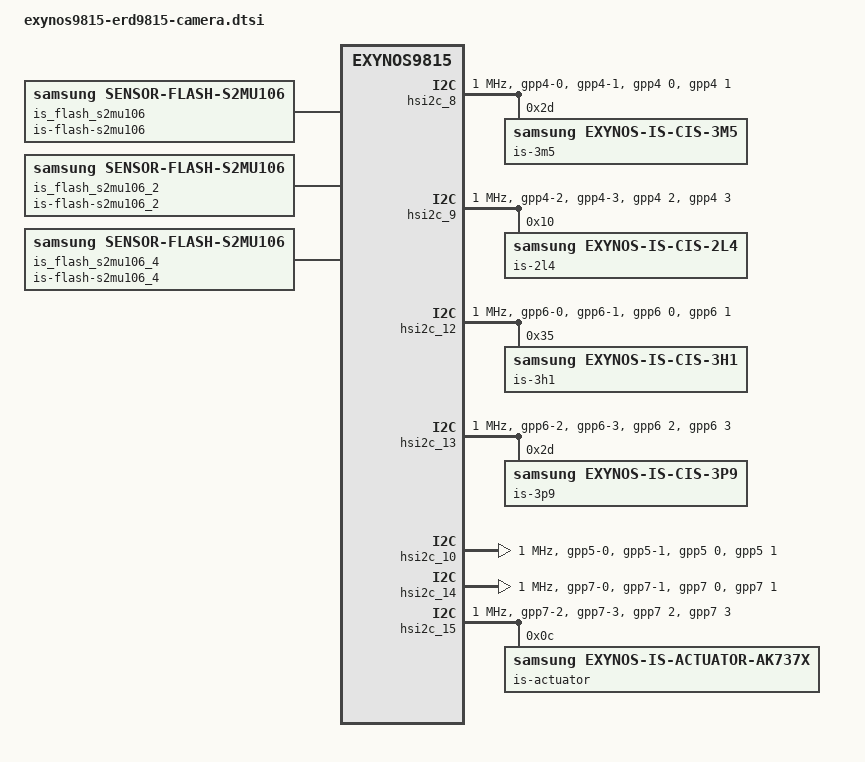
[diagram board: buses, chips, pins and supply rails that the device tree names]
/*
 * Samsung Exynos SoC series Pablo driver
 *
 * Copyright (c) 2020 Samsung Electronics Co., Ltd
 *
 * This program is free software; you can redistribute it and/or modify
 * it under the terms of the GNU General Public License version 2 as
 * published by the Free Software Foundation.
 */

#include <dt-bindings/camera/exynos_is_dt.h>

#include "camera/module_2l4.dtsi"
#include "camera/module_3m5.dtsi"
#include "camera/module_3p9.dtsi"
#include "camera/module_3h1.dtsi"

/ {
	fragment@camera {
		target-path = "/";
		__overlay__ {
			#address-cells = <2>;
			#size-cells = <1>;
			interrupt-parent = <&gic>;

			/* REAR CAMERA */
			is_sensor_2l4: is_sensor_2l4@20 {
				pinctrl-names = "pin0", "pin1", "pin2", "release";
				pinctrl-0 = <>;
				pinctrl-1 = <&sensor_mclk0_out>;
				pinctrl-2 = <&sensor_mclk0_fn>;
				pinctrl-3 = <>;

				/* board */
				position = <0>;	/* Rear:0. Front:1. Rear_sub:2. Secure:3. */
				id = <0>; /* is_sensor id */
				mclk_ch = <0>;
				sensor_i2c_ch = <1>; /* SENSOR_CONTROL_I2C1 */

				/* peri */
				af {
					product_name = <18>; /* ACTUATOR_NAME_AK737X : ak7371 or ak7374 */
					i2c_ch = <3>; /* SENSOR_CONTROL_I2C3 */
				};

				flash {
					product_name = <14>; /* S2MU106 */
				};

				ois {
					product_name = <100>; /* NOTHING */
				};

				vc_extra {
					/* ex) statX = <stat_type, sensor_mode, max_width, max_height, max_element> */
					stat0 = </* not avaliable */>;									/* VC_BUF_DATA_TYPE_SENSOR_STAT1 */
					stat1 = </*VC_STAT_TYPE_PDP_3_1_PDAF_STAT0*/ 1000 /*VC_SENSOR_MODE_2PD_MODE3*/ 102 1756 1 1>;	/* VC_BUF_DATA_TYPE_GENERAL_STAT1 */
					stat2 = </* not avaliable */>;									/* VC_BUF_DATA_TYPE_SENSOR_STAT2 */
					stat3 = </*VC_STAT_TYPE_PDP_3_1_PDAF_STAT1*/ 1001 /*VC_SENSOR_MODE_2PD_MODE3*/ 102 39424 1 1>;	/* VC_BUF_DATA_TYPE_GENERAL_STAT2 */
				};

				modes {
					mode0 {
						common = <4032 3024 30 0 0 CSI_DATA_LANES_4 2054 CSI_MODE_VC_DT LRTE_DISABLE PD_MOD3 EX_NONE>;
						vc3 = </* in */ 0 HW_FORMAT_EMBEDDED_8BIT 0 0	/* out */ HW_FORMAT_USER VC_PRIVATE 1756 1>;
					};
					mode1 {
						common = <4032 2268 60 0 1 CSI_DATA_LANES_4 2177 CSI_MODE_VC_DT LRTE_DISABLE PD_MOD3 EX_NONE>;
						vc3 = </* in */ 0 HW_FORMAT_EMBEDDED_8BIT 0 0	/* out */ HW_FORMAT_USER VC_PRIVATE 1756 1>;
					};
					mode2 {
						common = <4032 2268 30 0 2 CSI_DATA_LANES_4 2054 CSI_MODE_VC_DT LRTE_DISABLE PD_MOD3 EX_NONE>;
						vc3 = </* in */ 0 HW_FORMAT_EMBEDDED_8BIT 0 0	/* out */ HW_FORMAT_USER VC_PRIVATE 1756 1>;
					};
					mode3 {
						common = <4032 1908 30 0 3 CSI_DATA_LANES_4 2054 CSI_MODE_VC_DT LRTE_DISABLE PD_MOD3 EX_NONE>;
						vc3 = </* in */ 0 HW_FORMAT_EMBEDDED_8BIT 0 0	/* out */ HW_FORMAT_USER VC_PRIVATE 1756 1>;
					};
					mode4 {
						common = <3024 3024 30 0 4 CSI_DATA_LANES_4 2054 CSI_MODE_VC_DT LRTE_DISABLE PD_MOD3 EX_NONE>;
						vc3 = </* in */ 0 HW_FORMAT_EMBEDDED_8BIT 0 0	/* out */ HW_FORMAT_USER VC_PRIVATE 1756 1>;
					};
					mode5 {
						common = <2016 1512 30 0 5 CSI_DATA_LANES_4 1352 CSI_MODE_VC_DT LRTE_DISABLE PD_MOD3 EX_NONE>;
						vc3 = </* in */ 0 HW_FORMAT_EMBEDDED_8BIT 0 0	/* out */ HW_FORMAT_USER VC_PRIVATE 1756 1>;
					};
					mode6 {
						common = <2016 1134 30 0 6 CSI_DATA_LANES_4 1352 CSI_MODE_VC_DT LRTE_DISABLE PD_MOD3 EX_NONE>;
						vc3 = </* in */ 0 HW_FORMAT_EMBEDDED_8BIT 0 0	/* out */ HW_FORMAT_USER VC_PRIVATE 1756 1>;
					};
					mode7 {
						common = <1504 1504 30 0 7 CSI_DATA_LANES_4 1352 CSI_MODE_VC_DT LRTE_DISABLE PD_MOD3 EX_NONE>;
						vc3 = </* in */ 0 HW_FORMAT_EMBEDDED_8BIT 0 0	/* out */ HW_FORMAT_USER VC_PRIVATE 1756 1>;
					};
					/* MODE 3 - 24fps LIVE FOCUS */
					mode8 {
						common = <4032 3024 24 0 8 CSI_DATA_LANES_4 2054 CSI_MODE_VC_DT LRTE_DISABLE PD_MOD3 EX_LIVEFOCUS>;
						vc3 = </* in */ 0 HW_FORMAT_EMBEDDED_8BIT 0 0	/* out */ HW_FORMAT_USER VC_PRIVATE 1756 1>;
					};
					mode9 {
						common = <4032 2268 24 0 9 CSI_DATA_LANES_4 2054 CSI_MODE_VC_DT LRTE_DISABLE PD_MOD3 EX_LIVEFOCUS>;
						vc3 = </* in */ 0 HW_FORMAT_EMBEDDED_8BIT 0 0	/* out */ HW_FORMAT_USER VC_PRIVATE 1756 1>;
					};
					mode10 {
						common = <4032 1908 24 0 10 CSI_DATA_LANES_4 2054 CSI_MODE_VC_DT LRTE_DISABLE PD_MOD3 EX_LIVEFOCUS>;
						vc3 = </* in */ 0 HW_FORMAT_EMBEDDED_8BIT 0 0	/* out */ HW_FORMAT_USER VC_PRIVATE 1756 1>;
					};
					mode11 {
						common = <3024 3024 24 0 11 CSI_DATA_LANES_4 2054 CSI_MODE_VC_DT LRTE_DISABLE PD_MOD3 EX_LIVEFOCUS>;
						vc3 = </* in */ 0 HW_FORMAT_EMBEDDED_8BIT 0 0	/* out */ HW_FORMAT_USER VC_PRIVATE 1756 1>;
					};
					/* MODE 2 */
					mode12 {
						common = <2016 1134 240 0 12 CSI_DATA_LANES_4 2054 CSI_MODE_VC_DT LRTE_DISABLE PD_NONE EX_NONE>;
						vc3 = </* in */ 0 HW_FORMAT_EMBEDDED_8BIT 0 0	/* out */ HW_FORMAT_UNKNOWN VC_NOTHING 0 0>;
					};
					mode13 {
						common = <1008 756 120 0 13 CSI_DATA_LANES_4 2054 CSI_MODE_VC_DT LRTE_DISABLE PD_NONE EX_NONE>;
						vc3 = </* in */ 0 HW_FORMAT_EMBEDDED_8BIT 0 0	/* out */ HW_FORMAT_UNKNOWN VC_NOTHING 0 0>;
					};
				};

				power_seq {
					use = <1>;
					gpio_mclk = <&gpg1 0 0x1>;

					scenario_normal_on {
						sensor_scenario = <SENSOR_SCENARIO_NORMAL>;
						gpio_scenario = <GPIO_SCENARIO_ON>;

						/* A start node number should be over the 10 for reserved number 0~9. */
						/* pname = "name"; pin = <act value dealy voltage>; gpio = <gpx# # 0x1>; */
						10 { pname = "sen_rst low"; pin = <PIN_OUTPUT 0 0>; gpio = <&gpg3 1 0x1>; };
						20 { pname = "VDDD_RET_1.0V_CAM"; pin = <PIN_REGULATOR 1 1 1025000>; };
						30 { pname = "VDDA_2.8V_SUB"; pin = <PIN_REGULATOR 1 0>; };
						40 { pname = "VDDA_2.8V_CAM"; pin = <PIN_REGULATOR 1 1>; };
						50 { pname = "VDDD_1.05V_SUB"; pin = <PIN_REGULATOR 1 1>; };
						60 { pname = "VDD_VM_2.8V_OIS"; pin = <PIN_REGULATOR 1 1>; };
						70 { pname = "VDDIO_1.8V_CAM"; pin = <PIN_REGULATOR 1 1>; };
						80 { pname = "VDDD_1.05V_CAM"; pin = <PIN_REGULATOR 1 1000>; };
						90 { pname; pin; };
						100 { pname; pin; };
						110 { pname = "on_i2c"; pin = <PIN_I2C 1 0>; };
						120 { pname = "pin"; pin = <PIN_FUNCTION 2 0>; };
						130 { pname = "MCLK"; pin = <PIN_MCLK 1 1500>; share = <SRT_ACQUIRE SHARED_PIN0 1>; };
						140 { pname = "sen_rst high"; pin = <PIN_OUTPUT 1 3000>; gpio = <&gpg3 1 0x1>; };
						150 { pname; pin; gpio; };
					};

					scenario_vision_on {
						sensor_scenario = <SENSOR_SCENARIO_VISION>;
						gpio_scenario = <GPIO_SCENARIO_ON>;

						/* A start node number should be over the 10 for reserved number 0~9. */
						/* pname = "name"; pin = <act value dealy voltage>; gpio = <gpx# # 0x1>; */
						10 { pname = "sen_rst low"; pin = <PIN_OUTPUT 0 0>; gpio = <&gpg3 1 0x1>; };
						20 { pname = "VDDD_RET_1.0V_CAM"; pin = <PIN_REGULATOR 1 1 1025000>; };
						30 { pname = "VDDA_2.8V_SUB"; pin = <PIN_REGULATOR 1 0>; };
						40 { pname = "VDDA_2.8V_CAM"; pin = <PIN_REGULATOR 1 1>; };
						50 { pname = "VDDD_1.05V_SUB"; pin = <PIN_REGULATOR 1 1>; };
						60 { pname = "VDD_VM_2.8V_OIS"; pin = <PIN_REGULATOR 1 1>; };
						70 { pname = "VDDIO_1.8V_CAM"; pin = <PIN_REGULATOR 1 1>; };
						80 { pname = "VDDD_1.05V_CAM"; pin = <PIN_REGULATOR 1 1000>; };
						90 { pname; pin; };
						100 { pname; pin; };
						110 { pname = "on_i2c"; pin = <PIN_I2C 1 0>; };
						120 { pname = "pin"; pin = <PIN_FUNCTION 2 0>; };
						130 { pname = "MCLK"; pin = <PIN_MCLK 1 1500>; share = <SRT_ACQUIRE SHARED_PIN0 1>; };
						140 { pname = "sen_rst high"; pin = <PIN_OUTPUT 1 3000>; gpio = <&gpg3 1 0x1>; };
						150 { pname; pin; gpio; };
					};

					scenario_hw_init_normal_on {
						/* HW INIT (without ois power control) */
						sensor_scenario = <SENSOR_SCENARIO_HW_INIT>;
						gpio_scenario = <GPIO_SCENARIO_ON>;

						10 { pname; pin; gpio; };
						20 { pname; pin; gpio; };
						30 { pname; pin; gpio; };
						40 { pname; pin; gpio; };
						50 { pname; pin; gpio; };
						60 { pname; pin; gpio; };
						70 { pname; pin; gpio; };
						80 { pname; pin; gpio; };
						90 { pname; pin; gpio; };
						100 { pname; pin; gpio; };
						110 { pname; pin; gpio; };
						120 { pname; pin; gpio; };
					};

					scenario_normal_off {
						sensor_scenario = <SENSOR_SCENARIO_NORMAL>;
						gpio_scenario = <GPIO_SCENARIO_OFF>;

						/* A start node number should be over the 10 for reserved number 0~9. */
						/* pname = "name"; pin = <act value dealy voltage>; gpio = <gpx# # 0x1>; */
						10 { pname = "VDD_VM_2.8V_OIS"; pin = <PIN_REGULATOR 0 10>; };
						20 { pname = "VDDD_1.05V_CAM"; pin = <PIN_REGULATOR 0 1>; };
						30 { pname = "VDDD_1.05V_SUB"; pin = <PIN_REGULATOR 0 10>; };
						40 { pname = "VDDA_2.8V_SUB"; pin = <PIN_REGULATOR 0 0>; };
						50 { pname = "VDDA_2.8V_CAM"; pin = <PIN_REGULATOR 0 0>; };
						60 { pname = "MCLK"; pin = <PIN_MCLK 0 0>; share = <SRT_RELEASE SHARED_PIN0 0>; };
						70 { pname = "pin"; pin = <PIN_FUNCTION 0 0>; };
						80 { pname = "pin"; pin = <PIN_FUNCTION 1 0>; };
						90 { pname = "pin"; pin = <PIN_FUNCTION 0 0>; };
						100 { pname = "sen_rst low"; pin = <PIN_OUTPUT 0 10>; gpio = <&gpg3 1 0x1>; };
						110 { pname; pin; gpio; };
						120 { pname = "off_i2c"; pin = <PIN_I2C 0 0>; };
						130 { pname; pin; gpio; };
						140 { pname; pin; gpio; };
						150 { pname = "VDDD_RET_1.0V_CAM"; pin = <PIN_REGULATOR 0 100>; };
						160 { pname = "VDDIO_1.8V_CAM"; pin = <PIN_REGULATOR 0 10>; };
					};

					scenario_vision_off {
						sensor_scenario = <SENSOR_SCENARIO_VISION>;
						gpio_scenario = <GPIO_SCENARIO_OFF>;

						/* A start node number should be over the 10 for reserved number 0~9. */
						/* pname = "name"; pin = <act value dealy voltage>; gpio = <gpx# # 0x1>; */
						10 { pname = "VDD_VM_2.8V_OIS"; pin = <PIN_REGULATOR 0 10>; };
						20 { pname = "VDDD_1.05V_CAM"; pin = <PIN_REGULATOR 0 1>; };
						30 { pname = "VDDD_1.05V_SUB"; pin = <PIN_REGULATOR 0 10>; };
						40 { pname = "VDDA_2.8V_SUB"; pin = <PIN_REGULATOR 0 0>; };
						50 { pname = "VDDA_2.8V_CAM"; pin = <PIN_REGULATOR 0 0>; };
						60 { pname = "MCLK"; pin = <PIN_MCLK 0 0>; share = <SRT_RELEASE SHARED_PIN0 0>; };
						70 { pname = "pin"; pin = <PIN_FUNCTION 0 0>; };
						80 { pname = "pin"; pin = <PIN_FUNCTION 1 0>; };
						90 { pname = "pin"; pin = <PIN_FUNCTION 0 0>; };
						100 { pname = "sen_rst low"; pin = <PIN_OUTPUT 0 10>; gpio = <&gpg3 1 0x1>; };
						110 { pname; pin; gpio; };
						120 { pname = "off_i2c"; pin = <PIN_I2C 0 0>; };
						130 { pname; pin; gpio; };
						140 { pname; pin; gpio; };
						150 { pname = "VDDD_RET_1.0V_CAM"; pin = <PIN_REGULATOR 0 100>; };
						160 { pname = "VDDIO_1.8V_CAM"; pin = <PIN_REGULATOR 0 10>; };
					};

					scenario_retention_on {
						sensor_scenario = <SENSOR_SCENARIO_NORMAL>;
						gpio_scenario = <GPIO_SCENARIO_SENSOR_RETENTION_ON>;

						/* A start node number should be over the 10 for reserved number 0~9. */
						/* pname = "name"; pin = <act value dealy voltage>; gpio = <gpx# # 0x1>; */
						10 { pname; pin; gpio; };
						20 { pname; pin; gpio; };
						30 { pname; pin; gpio; };
						40 { pname; pin; gpio; };
						50 { pname; pin; gpio; };
						60 { pname; pin; gpio; };
						70 { pname; pin; gpio; };
						80 { pname; pin; gpio; };
						90 { pname; pin; gpio; };
						100 { pname; pin; gpio; };
						110 { pname; pin; gpio; };
						120 { pname; pin; gpio; };
						130 { pname; pin; gpio; };
						140 { pname; pin; gpio; };
						150 { pname; pin; gpio; };
					};

					scenario_hw_init_retention_on {
						/* RETENTION ON HW INIT(without ois power control) */
						sensor_scenario = <SENSOR_SCENARIO_HW_INIT>;
						gpio_scenario = <GPIO_SCENARIO_SENSOR_RETENTION_ON>;

						10 { pname; pin; gpio; };
						20 { pname; pin; gpio; };
						30 { pname; pin; gpio; };
						40 { pname; pin; gpio; };
						50 { pname; pin; gpio; };
						60 { pname; pin; gpio; };
						70 { pname; pin; gpio; };
						80 { pname; pin; gpio; };
						90 { pname; pin; gpio; };
						100 { pname; pin; gpio; };
						110 { pname; pin; gpio; };
						120 { pname; pin; gpio; };
					};

					scenario_ois_factory_on {
						sensor_scenario = <SENSOR_SCENARIO_OIS_FACTORY>;
						gpio_scenario = <GPIO_SCENARIO_ON>;

						/* A start node number should be over the 10 for reserved number 0~9. */
						/* pname = "name"; pin = <act value dealy voltage>; gpio = <gpx# # 0x1>; */
						10 { pname; pin; gpio; };
						20 { pname; pin; gpio; };
						30 { pname; pin; gpio; };
						40 { pname; pin; gpio; };
						50 { pname; pin; gpio; };
						60 { pname; pin; gpio; };
						70 { pname; pin; gpio; };
					};

					scenario_ois_factory_off {
						sensor_scenario = <SENSOR_SCENARIO_OIS_FACTORY>;
						gpio_scenario = <GPIO_SCENARIO_OFF>;

						/* A start node number should be over the 10 for reserved number 0~9. */
						/* pname = "name"; pin = <act value dealy voltage>; gpio = <gpx# # 0x1>; */
						10 { pname; pin; gpio; };
						20 { pname; pin; gpio; };
						30 { pname; pin; gpio; };
						40 { pname; pin; gpio; };
						50 { pname; pin; gpio; };
						60 { pname; pin; gpio; };
						70 { pname; pin; gpio; };
					};

					scenario_read_rom_on {
						sensor_scenario = <SENSOR_SCENARIO_READ_ROM>;
						gpio_scenario = <GPIO_SCENARIO_ON>;

						/* A start node number should be over the 10 for reserved number 0~9. */
						/* pname = "name"; pin = <act value dealy voltage>; gpio = <gpx# # 0x1>; */
						10 { pname; pin; gpio; };
						20 { pname; pin; gpio; };
						30 { pname; pin; gpio; };
						40 { pname; pin; gpio; };
					};

					scenario_read_rom_off {
						sensor_scenario = <SENSOR_SCENARIO_READ_ROM>;
						gpio_scenario = <GPIO_SCENARIO_OFF>;

						/* A start node number should be over the 10 for reserved number 0~9. */
						/* pname = "name"; pin = <act value dealy voltage>; gpio = <gpx# # 0x1>; */
						10 { pname; pin; gpio; };
						20 { pname; pin; gpio; };
						30 { pname; pin; gpio; };
						40 { pname; pin; gpio; };
					};
				};
			};

			/* Tele CAMERA */
			is_sensor_3m5: is_sensor_3m5@64 {
				pinctrl-names = "pin0", "pin1", "pin2", "release";
				pinctrl-0 = <>;
				pinctrl-1 = <&sensor_mclk0_out>;
				pinctrl-2 = <&sensor_mclk0_fn>;
				pinctrl-3 = <>;

				/* board */
				position = <2>; /* Rear:0. Front:1, Tele:2 */
				id = <2>; /* is_sensor id */
				mclk_ch = <0>;
				sensor_i2c_ch = <0>; /* SENSOR_CONTROL_I2C0 */

				af {
					product_name = <100>; /* NOTHING */
				};

				flash {
					product_name = <14>; /* S2MU106 */
				};

				preprocessor {
					product_name = <100>; /* NOTHING */
				};

				vc_extra {
					/* ex) statX = <stat_type, sensor_mode, max_width, max_height, max_element> */
					stat0 = </* not avaliable */>;			/* VC_BUF_DATA_TYPE_SENSOR_STAT1 */
					stat1 = </* not avaliable */>;			/* VC_BUF_DATA_TYPE_SENSOR_STAT1 */
					stat2 = </* not avaliable */>;			/* VC_BUF_DATA_TYPE_SENSOR_STAT2 */
					stat3 = </* not avaliable */>;			/* VC_BUF_DATA_TYPE_SENSOR_STAT2 */
				};

				/* sensor modes */
				modes {
					/* common = <width, height, fps, settle, mode, lane, speed, interleave, lrte, pd_mode> */
					/* vcX = <map, hwformat, width, height, hwformat, type, width, height> */
					mode0 {
						common = <4032 3024 30 0 0 CSI_DATA_LANES_4 1352 CSI_MODE_VC_ONLY LRTE_DISABLE PD_NONE EX_NONE>;
						vc1 = </* in */ 1 HW_FORMAT_RAW10 504 752	/* out */ HW_FORMAT_UNKNOWN VC_NOTHING 0 0>;
					};
					mode1 {
						common = <4032 2268 30 0 1 CSI_DATA_LANES_4 1352 CSI_MODE_VC_ONLY LRTE_DISABLE PD_NONE EX_NONE>;
						vc1 = </* in */ 1 HW_FORMAT_RAW10 504 560	/* out */ HW_FORMAT_UNKNOWN VC_NOTHING 0 0>;
					};
					mode2 {
						common = <3024 3024 30 0 2 CSI_DATA_LANES_4 1352 CSI_MODE_VC_ONLY LRTE_DISABLE PD_NONE EX_NONE>;
						vc1 = </* in */ 1 HW_FORMAT_RAW10 376 752	/* out */ HW_FORMAT_UNKNOWN VC_NOTHING 0 0>;
					};
					mode3 {
						common = <4032 1960 30 0 3 CSI_DATA_LANES_4 1352 CSI_MODE_VC_ONLY LRTE_DISABLE PD_NONE EX_NONE>;
						vc1 = </* in */ 1 HW_FORMAT_RAW10 504 480	/* out */ HW_FORMAT_UNKNOWN VC_NOTHING 0 0>;
					};
					mode4 {
						common = <4032 1908 30 0 4 CSI_DATA_LANES_4 1352 CSI_MODE_VC_ONLY LRTE_DISABLE PD_NONE EX_NONE>;
						vc1 = </* in */ 1 HW_FORMAT_RAW10 504 464	/* out */ HW_FORMAT_UNKNOWN VC_NOTHING 0 0>;
					};
					mode5 {
						common = <1920 1080 60 0 5 CSI_DATA_LANES_4 1352 CSI_MODE_VC_ONLY LRTE_DISABLE PD_NONE EX_NONE>;
						vc1 = </* in */ 1 HW_FORMAT_RAW10 240 256	/* out */ HW_FORMAT_UNKNOWN VC_NOTHING 0 0>;
					};
					mode7 {
						common = <2016 1512 30 0 7 CSI_DATA_LANES_4 1352 CSI_MODE_VC_ONLY LRTE_DISABLE PD_NONE EX_NONE>;
						vc1 = </* in */ 1 HW_FORMAT_RAW10 504 752	/* out */ HW_FORMAT_UNKNOWN VC_NOTHING 0 0>;
					};
					mode8 {
						common = <1504 1504 30 0 8 CSI_DATA_LANES_4 1352 CSI_MODE_VC_ONLY LRTE_DISABLE PD_NONE EX_NONE>;
						vc1 = </* in */ 1 HW_FORMAT_RAW10 376 752	/* out */ HW_FORMAT_UNKNOWN VC_NOTHING 0 0>;
					};
					mode9 {
						common = <2016 1134 30 0 9 CSI_DATA_LANES_4 1352 CSI_MODE_VC_ONLY LRTE_DISABLE PD_NONE EX_NONE>;
						vc1 = </* in */ 1 HW_FORMAT_RAW10 504 560	/* out */ HW_FORMAT_UNKNOWN VC_NOTHING 0 0>;
					};
				};

				power_seq {
					use = <1>;
					gpio_mclk = <&gpg1 0 0x1>;

					scenario_normal_on {
						sensor_scenario = <SENSOR_SCENARIO_NORMAL>;
						gpio_scenario = <GPIO_SCENARIO_ON>;

						/* A start node number should be over the 10 for reserved number 0~9. */
						/* pname = "name"; pin = <act value dealy voltage>; gpio = <gpx# # 0x1>; */
						10 { pname = "sen_rst low"; pin = <PIN_OUTPUT 0 0>; gpio = <&gpg3 2 0x1>; };
						20 { pname = "S2MPB02_LDO11"; pin = <PIN_REGULATOR 1 1>; };
						30 { pname = "S2MPB02_LDO1"; pin = <PIN_REGULATOR 1 1>; };
						40 { pname = "S2MPB02_LDO12"; pin = <PIN_REGULATOR 1 1>; };
						50 { pname = "S2MPB02_LDO7"; pin = <PIN_REGULATOR 1 1000>; };
						60 { pname = "on_i2c"; pin = <PIN_I2C 1 0>; };
						70 { pname = "sen_rst high"; pin = <PIN_OUTPUT 1 0>; gpio = <&gpg3 2 0x1>; };
						80 { pname = "pin"; pin = <PIN_FUNCTION 2 0>; };
						90 { pname = "MCLK"; pin = <PIN_MCLK 1 1000>; share = <SRT_ACQUIRE SHARED_PIN0 1>; };
					};

					scenario_vision_on {
						sensor_scenario = <SENSOR_SCENARIO_VISION>;
						gpio_scenario = <GPIO_SCENARIO_ON>;

						/* A start node number should be over the 10 for reserved number 0~9. */
						/* pname = "name"; pin = <act value dealy voltage>; gpio = <gpx# # 0x1>; */
						10 { pname = "sen_rst low"; pin = <PIN_OUTPUT 0 0>; gpio = <&gpg3 2 0x1>; };
						20 { pname = "S2MPB02_LDO11"; pin = <PIN_REGULATOR 1 1>; };
						30 { pname = "S2MPB02_LDO1"; pin = <PIN_REGULATOR 1 1>; };
						40 { pname = "S2MPB02_LDO12"; pin = <PIN_REGULATOR 1 1>; };
						50 { pname = "S2MPB02_LDO7"; pin = <PIN_REGULATOR 1 1000>; };
						60 { pname = "on_i2c"; pin = <PIN_I2C 1 0>; };
						70 { pname = "sen_rst high"; pin = <PIN_OUTPUT 1 0>; gpio = <&gpg3 2 0x1>; };
						80 { pname = "pin"; pin = <PIN_FUNCTION 2 0>; };
						90 { pname = "MCLK"; pin = <PIN_MCLK 1 1000>; share = <SRT_ACQUIRE SHARED_PIN0 1>; };
					};

					scenario_normal_off {
						sensor_scenario = <SENSOR_SCENARIO_NORMAL>;
						gpio_scenario = <GPIO_SCENARIO_OFF>;

						/* A start node number should be over the 10 for reserved number 0~9. */
						/* pname = "name"; pin = <act value dealy voltage>; gpio = <gpx# # 0x1>; */
						10 { pname = "sen_rst low"; pin = <PIN_OUTPUT 0 10>; gpio = <&gpg3 2 0x1>; };
						20 { pname = "off_i2c"; pin = <PIN_I2C 0 0>; };
						30 { pname = "S2MPB02_LDO12"; pin = <PIN_REGULATOR 0 1>; };
						40 { pname = "S2MPB02_LDO11"; pin = <PIN_REGULATOR 0 1>; };
						50 { pname = "S2MPB02_LDO7"; pin = <PIN_REGULATOR 0 1>; };
						60 { pname = "S2MPB02_LDO1"; pin = <PIN_REGULATOR 0 100>; };
						70 { pname = "MCLK"; pin = <PIN_MCLK 0 1>; };
						80 { pname = "pin"; pin = <PIN_FUNCTION 0 0>; };
						90 { pname = "pin"; pin = <PIN_FUNCTION 1 0>; };
						100 { pname = "pin"; pin = <PIN_FUNCTION 0 0>; share = <SRT_RELEASE SHARED_PIN0 0>; };
					};

					scenario_vision_off {
						sensor_scenario = <SENSOR_SCENARIO_VISION>;
						gpio_scenario = <GPIO_SCENARIO_OFF>;

						/* A start node number should be over the 10 for reserved number 0~9. */
						/* pname = "name"; pin = <act value dealy voltage>; gpio = <gpx# # 0x1>; */
						10 { pname = "sen_rst low"; pin = <PIN_OUTPUT 0 10>; gpio = <&gpg3 2 0x1>; };
						20 { pname = "off_i2c"; pin = <PIN_I2C 0 0>; };
						30 { pname = "S2MPB02_LDO12"; pin = <PIN_REGULATOR 0 1>; };
						40 { pname = "S2MPB02_LDO11"; pin = <PIN_REGULATOR 0 1>; };
						50 { pname = "S2MPB02_LDO7"; pin = <PIN_REGULATOR 0 1>; };
						60 { pname = "S2MPB02_LDO1"; pin = <PIN_REGULATOR 0 100>; };
						70 { pname = "MCLK"; pin = <PIN_MCLK 0 1>; };
						80 { pname = "pin"; pin = <PIN_FUNCTION 0 0>; };
						90 { pname = "pin"; pin = <PIN_FUNCTION 1 0>; };
						100 { pname = "pin"; pin = <PIN_FUNCTION 0 0>; share = <SRT_RELEASE SHARED_PIN0 0>; };
					};
				};
			};

			/* Ultra Wide CAMERA */
			is_sensor_3p9: is_sensor_3p9@2D {
				pinctrl-names = "pin0", "pin1", "pin2", "release";
				pinctrl-0 = <>;
				pinctrl-1 = <&sensor_mclk1_out>;
				pinctrl-2 = <&sensor_mclk1_fn>;
				pinctrl-3 = <>;

				/* board */
				position = <4>; /* Rear:0. Front:1, Tele:2 */
				id = <4>; /* is_sensor id */
				mclk_ch = <1>;
				sensor_i2c_ch = <5>; /* SENSOR_CONTROL_I2C5 */

				af {
					product_name = <100>; /* NOTHING */
				};

				flash {
					product_name = <14>; /* S2MU106 */
				};

				preprocessor {
					product_name = <100>; /* NOTHING */
				};

				ois {
					product_name = <100>; /* NOTHING */
				};

				power_seq {
					use = <1>;
					gpio_mclk = <&gpg1 1 0x1>;

					scenario_normal_on {
						sensor_scenario = <SENSOR_SCENARIO_NORMAL>;
						gpio_scenario = <GPIO_SCENARIO_ON>;

						/* A start node number should be over the 10 for reserved number 0~9. */
						/* pname = "name"; pin = <act value dealy voltage>; gpio = <gpx# # 0x1>; */
						10 { pname = "sen_rst low"; pin = <PIN_OUTPUT 0 0>; gpio = <&gpg3 3 0x1>; };
						20 { pname = "S2MPB02_LDO15"; pin = <PIN_REGULATOR 1 0>; };
						30 { pname = "S2MPB02_LDO8"; pin = <PIN_REGULATOR 1 0>; };
						40 { pname = "S2MPB02_LDO4"; pin = <PIN_REGULATOR 1 0>; };
						50 { pname = "on_i2c"; pin = <PIN_I2C 1 0>; };
						60 { pname = "pin"; pin = <PIN_FUNCTION 2 0>; };
						70 { pname = "MCLK"; pin = <PIN_MCLK 1 0>; };
						80 { pname = "sen_rst high"; pin = <PIN_OUTPUT 1 0>; gpio = <&gpg3 3 0x1>; };
					};

					scenario_normal_off {
						sensor_scenario = <SENSOR_SCENARIO_NORMAL>;
						gpio_scenario = <GPIO_SCENARIO_OFF>;

						/* A start node number should be over the 10 for reserved number 0~9. */
						/* pname = "name"; pin = <act value dealy voltage>; gpio = <gpx# # 0x1>; */
						10 { pname = "S2MPB02_LDO15"; pin = <PIN_REGULATOR 0 0>; };
						20 { pname = "S2MPB02_LDO4"; pin = <PIN_REGULATOR 0 0>; };
						30 { pname = "MCLK"; pin = <PIN_MCLK 0 0>; };
						40 { pname = "pin"; pin = <PIN_FUNCTION 0 0>; };
						50 { pname = "sen_rst"; pin = <PIN_OUTPUT 0 0>; gpio = <&gpg3 3 0x1>; };
						60 { pname = "off_i2c"; pin = <PIN_I2C 0 0>; };
						70 { pname = "S2MPB02_LDO8"; pin = <PIN_REGULATOR 0 0>; };
					};

					scenario_vision_on {
						sensor_scenario = <SENSOR_SCENARIO_VISION>;
						gpio_scenario = <GPIO_SCENARIO_ON>;

						/* A start node number should be over the 10 for reserved number 0~9. */
						/* pname = "name"; pin = <act value dealy voltage>; gpio = <gpx# # 0x1>; */
						10 { pname = "sen_rst low"; pin = <PIN_OUTPUT 0 0>; gpio = <&gpg3 3 0x1>; };
						20 { pname = "S2MPB02_LDO15"; pin = <PIN_REGULATOR 1 0>; };
						30 { pname = "S2MPB02_LDO8"; pin = <PIN_REGULATOR 1 0>; };
						40 { pname = "S2MPB02_LDO4"; pin = <PIN_REGULATOR 1 0>; };
						50 { pname = "on_i2c"; pin = <PIN_I2C 1 0>; };
						60 { pname = "pin"; pin = <PIN_FUNCTION 2 0>; };
						70 { pname = "MCLK"; pin = <PIN_MCLK 1 0>; };
						80 { pname = "sen_rst high"; pin = <PIN_OUTPUT 1 0>; gpio = <&gpg3 3 0x1>; };
					};

					scenario_vision_off {
						sensor_scenario = <SENSOR_SCENARIO_VISION>;
						gpio_scenario = <GPIO_SCENARIO_OFF>;

						/* A start node number should be over the 10 for reserved number 0~9. */
						/* pname = "name"; pin = <act value dealy voltage>; gpio = <gpx# # 0x1>; */
						10 { pname = "S2MPB02_LDO15"; pin = <PIN_REGULATOR 0 0>; };
						20 { pname = "S2MPB02_LDO4"; pin = <PIN_REGULATOR 0 0>; };
						30 { pname = "MCLK"; pin = <PIN_MCLK 0 0>; };
						40 { pname = "pin"; pin = <PIN_FUNCTION 0 0>; };
						50 { pname = "sen_rst"; pin = <PIN_OUTPUT 0 0>; gpio = <&gpg3 3 0x1>; };
						60 { pname = "off_i2c"; pin = <PIN_I2C 0 0>; };
						70 { pname = "S2MPB02_LDO8"; pin = <PIN_REGULATOR 0 0>; };
					};
				};
			};

			/* FRONT CAMERA */
			is_sensor_3h1: is_sensor_3h1@31 {
				pinctrl-names = "pin0", "pin1", "pin2", "release";
				pinctrl-0 = <>;
				pinctrl-1 = <&sensor_mclk2_out>;
				pinctrl-2 = <&sensor_mclk2_fn>;
				pinctrl-3 = <>;

				/* board */
				position = <1>;	/* Rear:0. Front:1. Rear_sub:2. Secure:3. */
				id = <1>; /* is_sensor id */
				mclk_ch = <2>;
				sensor_i2c_ch = <4>; /* SENSOR_CONTROL_I2C4 */

				/* peri*/
				af {
					product_name = <18>; /* ACTUATOR_NAME_AK737X */
					i2c_ch = <7>; /* SENSOR_CONTROL_I2C7 */
				};

				flash {
					product_name = <100>; /* NOTHING */
				};

				ois {
					product_name = <100>; /* NOTHING */
				};

				vc_extra {
					/* ex) statX = <stat_type, sensor_mode, max_width, max_height, max_element> */
					stat0 = </* not avaliable */>;									/* VC_BUF_DATA_TYPE_SENSOR_STAT1 */
					stat1 = </* not avaliable */>;									/* VC_BUF_DATA_TYPE_SENSOR_STAT1 */
					stat2 = </* not avaliable */>;									/* VC_BUF_DATA_TYPE_SENSOR_STAT2 */
					stat3 = </* not avaliable */>;									/* VC_BUF_DATA_TYPE_SENSOR_STAT2 */
				};

				power_seq {
					use = <1>;
					gpio_mclk = <&gpg1 2 0x1>;

					scenario_normal_on {
						sensor_scenario = <SENSOR_SCENARIO_NORMAL>;
						gpio_scenario = <GPIO_SCENARIO_ON>;

						/* A start node number should be over the 10 for reserved number 0~9. */
						/* pname = "name"; pin = <act value dealy voltage>; gpio = <gpx# # 0x1>; */
						10 { pname = "sen_rst low"; pin = <PIN_OUTPUT 0 0>; gpio = <&gpg3 4 0x1>; };
						20 { pname = "S2MPB02_LDO16"; pin = <PIN_REGULATOR 1 1>; };
						30 { pname = "S2MPB02_LDO13"; pin = <PIN_REGULATOR 1 1>; };
						40 { pname = "S2MPB02_LDO6"; pin = <PIN_REGULATOR 1 1>; };
						50 { pname = "S2MPB02_LDO5"; pin = <PIN_REGULATOR 1 1000>; };
						60 { pname = "on_i2c"; pin = <PIN_I2C 1 0>; };
						70 { pname = "sen_rst high"; pin = <PIN_OUTPUT 1 0>; gpio = <&gpg3 4 0x1>; };
						80 { pname = "pin"; pin = <PIN_FUNCTION 2 0>; };
						90 { pname = "MCLK"; pin = <PIN_MCLK 1 9000>; };
					};

					scenario_vision_on {
						sensor_scenario = <SENSOR_SCENARIO_VISION>;
						gpio_scenario = <GPIO_SCENARIO_ON>;

						/* A start node number should be over the 10 for reserved number 0~9. */
						/* pname = "name"; pin = <act value dealy voltage>; gpio = <gpx# # 0x1>; */
						10 { pname = "sen_rst low"; pin = <PIN_OUTPUT 0 0>; gpio = <&gpg3 4 0x1>; };
						20 { pname = "S2MPB02_LDO16"; pin = <PIN_REGULATOR 1 1>; };
						30 { pname = "S2MPB02_LDO13"; pin = <PIN_REGULATOR 1 1>; };
						40 { pname = "S2MPB02_LDO6"; pin = <PIN_REGULATOR 1 1>; };
						50 { pname = "S2MPB02_LDO5"; pin = <PIN_REGULATOR 1 1000>; };
						60 { pname = "on_i2c"; pin = <PIN_I2C 1 0>; };
						70 { pname = "sen_rst high"; pin = <PIN_OUTPUT 1 0>; gpio = <&gpg3 4 0x1>; };
						80 { pname = "pin"; pin = <PIN_FUNCTION 2 0>; };
						90 { pname = "MCLK"; pin = <PIN_MCLK 1 9000>; };
					};

					scenario_normal_off {
						sensor_scenario = <SENSOR_SCENARIO_NORMAL>;
						gpio_scenario = <GPIO_SCENARIO_OFF>;

						/* A start node number should be over the 10 for reserved number 0~9. */
						/* pname = "name"; pin = <act value dealy voltage>; gpio = <gpx# # 0x1>; */
						10 { pname = "MCLK"; pin = <PIN_MCLK 0 1>; };
						20 { pname = "pin"; pin = <PIN_FUNCTION 0 0>; };
						30 { pname = "pin"; pin = <PIN_FUNCTION 1 0>; };
						40 { pname = "pin"; pin = <PIN_FUNCTION 0 0>; };
						50 { pname = "sen_rst low"; pin = <PIN_OUTPUT 0 10>; gpio = <&gpg3 4 0x1>; };
						60 { pname = "off_i2c"; pin = <PIN_I2C 0 0>; };
						70 { pname = "S2MPB02_LDO16"; pin = <PIN_REGULATOR 0 1>; };
						80 { pname = "S2MPB02_LDO13"; pin = <PIN_REGULATOR 0 1>; };
						90 { pname = "S2MPB02_LDO6"; pin = <PIN_REGULATOR 0 1>; };
						100 { pname = "S2MPB02_LDO5"; pin = <PIN_REGULATOR 0 100>; };
					};

					scenario_vision_off {
						sensor_scenario = <SENSOR_SCENARIO_VISION>;
						gpio_scenario = <GPIO_SCENARIO_OFF>;

						/* A start node number should be over the 10 for reserved number 0~9. */
						/* pname = "name"; pin = <act value dealy voltage>; gpio = <gpx# # 0x1>; */
						10 { pname = "MCLK"; pin = <PIN_MCLK 0 1>; };
						20 { pname = "pin"; pin = <PIN_FUNCTION 0 0>; };
						30 { pname = "pin"; pin = <PIN_FUNCTION 1 0>; };
						40 { pname = "pin"; pin = <PIN_FUNCTION 0 0>; };
						50 { pname = "sen_rst low"; pin = <PIN_OUTPUT 0 10>; gpio = <&gpg3 4 0x1>; };
						60 { pname = "off_i2c"; pin = <PIN_I2C 0 0>; };
						70 { pname = "S2MPB02_LDO16"; pin = <PIN_REGULATOR 0 1>; };
						80 { pname = "S2MPB02_LDO13"; pin = <PIN_REGULATOR 0 1>; };
						90 { pname = "S2MPB02_LDO6"; pin = <PIN_REGULATOR 0 1>; };
						100 { pname = "S2MPB02_LDO5"; pin = <PIN_REGULATOR 0 100>; };
					};

					scenario_read_rom_on {
						sensor_scenario = <SENSOR_SCENARIO_READ_ROM>;
						gpio_scenario = <GPIO_SCENARIO_ON>;

						/* A start node number should be over the 10 for reserved number 0~9. */
						/* pname = "name"; pin = <act value dealy voltage>; gpio = <gpx# # 0x1>; */
						10 { pname; pin; gpio; };
						20 { pname; pin; gpio; };
					};

					scenario_read_rom_off {
						sensor_scenario = <SENSOR_SCENARIO_READ_ROM>;
						gpio_scenario = <GPIO_SCENARIO_OFF>;

						/* A start node number should be over the 10 for reserved number 0~9. */
						/* pname = "name"; pin = <act value dealy voltage>; gpio = <gpx# # 0x1>; */
						10 { pname; pin; gpio; };
						20 { pname; pin; gpio; };
					};
				};
			};

			is_flash_s2mu106: is-flash-s2mu106@0 {
				compatible = "samsung,sensor-flash-s2mu106";
				id = <0>;
				led_ch = <1 2>;
				status = "okay";
			};

			is_flash_s2mu106_2: is-flash-s2mu106_2@0 {
				compatible = "samsung,sensor-flash-s2mu106";
				id = <2>;
				led_ch = <1 2>;
				status = "okay";
			};

			is_flash_s2mu106_4: is-flash-s2mu106_4@0 {
				compatible = "samsung,sensor-flash-s2mu106";
				id = <4>;
				led_ch = <1 2>;
				status = "okay";
			};

			/* REAR CAMERA */
			is_sensor0: is_sensor0@17030000 {
				#address-cells = <1>;
				#size-cells = <1>;
				scenario = <SENSOR_SCENARIO_NORMAL>;	/* Normal, Vision, OIS etc */
				id = <0>;
				csi_ch = <0>;
				status = "okay";
				use_cphy = <0>;

				interrupts = <0 INTREQ__CSIS0 IRQ_TYPE_LEVEL_HIGH>; /*MIPI-CSI0 */
				interrupt-names = "csi";
			};

			/* FRONT CAMERA */
			is_sensor1: is_sensor1@17040000 {
				#address-cells = <1>;
				#size-cells = <1>;
				reg = <0x0 0x17070000 0x1000>, /* MIPI-CSI4 */
					<0x0 0x170A0000 0x10000>; /* PHY: M0S4S4S4S4S4S2 */
				scenario = <SENSOR_SCENARIO_NORMAL>;    /* Normal, Vision, OIS etc */
				id = <1>;
				csi_ch = <4>;
				status = "okay";

				interrupts = <0 INTREQ__CSIS4 IRQ_TYPE_LEVEL_HIGH>; /* MIPI-CSI4 */
				interrupt-names = "csi";
				phys = <&mipi_phy_csis4_m0s4s4s4s4s4s2 0>;
			};

			/* Tele CAMERA */
			is_sensor2: is_sensor2@17050000 {
				#address-cells = <1>;
				#size-cells = <1>;
				reg = <0x0 0x17040000 0x1000>, /* MIPI-CSI1 */
					<0x0 0x170A0000 0x10000>; /* PHY: M0S4S4S4S4S4S2 */
				scenario = <SENSOR_SCENARIO_NORMAL>;    /* Normal, Vision, OIS etc */
				id = <2>;
				csi_ch = <1>;
				status = "okay";
				use_cphy = <0>;

				interrupts = <0 INTREQ__CSIS1 IRQ_TYPE_LEVEL_HIGH>; /* MIPI-CSI1 */
				interrupt-names = "csi";
				phys = <&mipi_phy_csis1_m0s4s4s4s4s4s2 0>;
			};

			/* ULTRA WIDE CAMERA */
			is_sensor4: is_sensor4@17070000 {
				#address-cells = <1>;
				#size-cells = <1>;
				reg = <0x0 0x17060000 0x1000>, /* MIPI-CSI3 */
					<0x0 0x170A0000 0x10000>; /* PHY: M0S4S4S4S4S4S2 */
				scenario = <SENSOR_SCENARIO_NORMAL>;    /* Normal, Vision, OIS etc */
				id = <4>;
				csi_ch = <3>;
				status = "okay";
				use_cphy = <0>;

				interrupts = <0 INTREQ__CSIS3 IRQ_TYPE_LEVEL_HIGH>; /* MIPI-CSI3 */
				phys = <&mipi_phy_csis3_m0s4s4s4s4s4s2 0>;
			};
		}; /* end of __overlay__ */
	}; /* end of fragment */
}; /* end of root */

/***** reference symbol node *****/
/* GPIO_PERI */
&pinctrl_4 {
	/* REAR TELE : i2c0 */
	hsi2c8_bus: hsi2c8-bus {
		samsung,pins = "gpp4-0", "gpp4-1";
		samsung,pin-function = <2>;
		samsung,pin-pud = <3>;
		samsung,pin-drv = <0>;
	};

	hsi2c8_bus_in: hsi2c8-bus-in {
		samsung,pins = "gpp4-0", "gpp4-1";
		samsung,pin-function = <0>;
		samsung,pin-pud = <3>;
		samsung,pin-drv = <0>;
	};

	/* REAR WIDE : i2c1 */
	hsi2c9_bus: hsi2c9-bus {
		samsung,pins = "gpp4-2", "gpp4-3";
		samsung,pin-function = <3>;
		samsung,pin-pud = <3>;
		samsung,pin-drv = <0>;
	};

	hsi2c9_bus_in: hsi2c9-bus-in {
		samsung,pins = "gpp4-2", "gpp4-3";
		samsung,pin-function = <0>;
		samsung,pin-pud = <3>;
		samsung,pin-drv = <0>;
	};

	/* REAR OIS i2c2 */
	hsi2c10_bus: hsi2c10-bus {
		samsung,pins = "gpp5-0", "gpp5-1";
		samsung,pin-function = <2>;
		samsung,pin-pud = <3>;
		samsung,pin-drv = <0>;
	};

	hsi2c10_bus_in: hsi2c10-bus-n {
		samsung,pins = "gpp5-0", "gpp5-1";
		samsung,pin-function = <0>;
		samsung,pin-pud = <3>;
		samsung,pin-drv = <0>;
	};

	/* FRONT i2c4 */
	hsi2c12_bus: hsi2c12-bus {
		samsung,pins = "gpp6-0", "gpp6-1";
		samsung,pin-function = <2>;
		samsung,pin-pud = <3>;
		samsung,pin-drv = <0>;
	};

	hsi2c12_bus_in: hsi2c12-bus-in {
		samsung,pins = "gpp6-0", "gpp6-1";
		samsung,pin-function = <0>;
		samsung,pin-pud = <3>;
		samsung,pin-drv = <0>;
	};

	/* REAR UWIDE i2c5 */
	hsi2c13_bus: hsi2c13-bus {
		samsung,pins = "gpp6-2", "gpp6-3";
		samsung,pin-function = <3>;
		samsung,pin-pud = <3>;
		samsung,pin-drv = <0>;
	};

	hsi2c13_bus_in: hsi2c13-bus-in {
		samsung,pins = "gpp6-2", "gpp6-3";
		samsung,pin-function = <0>;
		samsung,pin-pud = <3>;
		samsung,pin-drv = <0>;
	};

	/* REAR TEST CAM i2c6 */
	hsi2c14_bus: hsi2c14-bus {
		samsung,pins = "gpp7-0", "gpp7-1";
		samsung,pin-function = <2>;
		samsung,pin-pud = <3>;
		samsung,pin-drv = <0>;
	};

	hsi2c14_bus_in: hsi2c14-bus-in {
		samsung,pins = "gpp7-0", "gpp7-1";
		samsung,pin-function = <0>;
		samsung,pin-pud = <3>;
		samsung,pin-drv = <0>;
	};

	/* FRONT EEP/ACT i2c7 */
	hsi2c15_bus: hsi2c15-bus {
		samsung,pins = "gpp7-2", "gpp7-3";
		samsung,pin-function = <3>;
		samsung,pin-pud = <3>;
		samsung,pin-drv = <0>;
	};

	hsi2c15_bus_in: hsi2c15-bus-in {
		samsung,pins = "gpp7-2", "gpp7-3";
		samsung,pin-function = <0>;
		samsung,pin-pud = <3>;
		samsung,pin-drv = <0>;
	};
};

&hsi2c_8 {
	#address-cells = <1>;
	#size-cells = <0>;
	gpios = <&gpp4 0 0 &gpp4 1 0>;
	status = "okay";
	clock-frequency = <1000000>;
	samsung,reset-before-trans;
	samsung,fast-plus-mode;

	pinctrl-names = "default","on_i2c","off_i2c";
	pinctrl-0 = <&hsi2c8_bus_in>;
	pinctrl-1 = <&hsi2c8_bus>;
	pinctrl-2 = <&hsi2c8_bus_in>;

	is-3m5@10 {
		compatible = "samsung,exynos-is-cis-3m5";
		reg = <0x2D>; /* 1 bit right shift */
		id = <2>; /* matching is_sensor id */
		setfile = "setA";
		status = "okay";
	};
};

&hsi2c_9 {
	#address-cells = <1>;
	#size-cells = <0>;
	gpios = <&gpp4 2 0 &gpp4 3 0>;
	status = "okay";
	clock-frequency = <1000000>;
	samsung,reset-before-trans;
	samsung,fast-plus-mode;

	pinctrl-names = "default","on_i2c","off_i2c";
	pinctrl-0 = <&hsi2c9_bus_in>;
	pinctrl-1 = <&hsi2c9_bus>;
	pinctrl-2 = <&hsi2c9_bus_in>;

	is-2l4@10 {
		compatible = "samsung,exynos-is-cis-2l4";
		reg = <0x10>; /* 1 bit right shift */
		id = <0>; /* matching is_sensor id */
		setfile = "setB";
		status = "okay";
	};
};

&hsi2c_12 {
	#address-cells = <1>;
	#size-cells = <0>;
	gpios = <&gpp6 0 0 &gpp6 1 0>;
	status = "okay";
	clock-frequency = <1000000>;
	samsung,reset-before-trans;
	samsung,fast-plus-mode;

	pinctrl-names = "default","on_i2c","off_i2c";
	pinctrl-0 = <&hsi2c12_bus_in>;
	pinctrl-1 = <&hsi2c12_bus>;
	pinctrl-2 = <&hsi2c12_bus_in>;

	is-3h1@35 {
		compatible = "samsung,exynos-is-cis-3h1";
		reg = <0x35>; /* 1 bit right shift */
		id = <1>; /* matching is_sensor id */
		setfile = "setA";
		status = "okay";
	};
};

&hsi2c_13 {
	#address-cells = <1>;
	#size-cells = <0>;
	gpios = <&gpp6 2 0 &gpp6 3 0>;
	status = "okay";
	clock-frequency = <1000000>;
	samsung,reset-before-trans;
	samsung,fast-plus-mode;

	pinctrl-names = "default","on_i2c","off_i2c";
	pinctrl-0 = <&hsi2c13_bus_in>;
	pinctrl-1 = <&hsi2c13_bus>;
	pinctrl-2 = <&hsi2c13_bus_in>;

	is-3p9@2d {
		compatible = "samsung,exynos-is-cis-3p9";
		reg = <0x2d>; /* 1 bit right shift */
		id = <4>; /* matching is_sensor id */
		setfile = "setA";
		status = "okay";
	};
};

&hsi2c_10 {
	#address-cells = <1>;
	#size-cells = <0>;
	gpios = <&gpp5 0 0 &gpp5 1 0>;
	status = "okay";
	clock-frequency = <1000000>;
	samsung,reset-before-trans;
	samsung,fast-plus-mode;

	pinctrl-names = "default","on_i2c","off_i2c";
	pinctrl-0 = <&hsi2c10_bus_in>;
	pinctrl-1 = <&hsi2c10_bus>;
	pinctrl-2 = <&hsi2c10_bus_in>;

	is-dummy@01 {
		compatible = "samsung,exynos-is-dummy";
		reg = <0x10>;
		status = "okay";
	};
};

&hsi2c_14 {
	#address-cells = <1>;
	#size-cells = <0>;
	gpios = <&gpp7 0 0 &gpp7 1 0>;
	status = "okay";
	clock-frequency = <1000000>;
	samsung,reset-before-trans;
	samsung,fast-plus-mode;

	pinctrl-names = "default","on_i2c","off_i2c";
	pinctrl-0 = <&hsi2c14_bus_in>;
	pinctrl-1 = <&hsi2c14_bus>;
	pinctrl-2 = <&hsi2c14_bus_in>;

	is-dummy@02 {
		compatible = "samsung,exynos-is-dummy";
		reg = <0x10>;
		status = "okay";
	};
};

&hsi2c_15 {
	#address-cells = <1>;
	#size-cells = <0>;
	gpios = <&gpp7 2 0 &gpp7 3 0>;
	status = "okay";
	clock-frequency = <1000000>;
	samsung,reset-before-trans;
	samsung,fast-plus-mode;

	pinctrl-names = "default","on_i2c","off_i2c";
	pinctrl-0 = <&hsi2c15_bus_in>;
	pinctrl-1 = <&hsi2c15_bus>;
	pinctrl-2 = <&hsi2c15_bus_in>;

	is-actuator@0C {
		compatible = "samsung,exynos-is-actuator-ak737x";
		reg = <0x0C>;
		id = <1>; /* matching is_sensor id */
		/* AK737x: addr 0xF3, data 0x0E */
		vendor_product_id = <0xF3 0x0E 0xF3 0x13 0xF3 0x00>;
		vendor_first_pos = <120>;
		vendor_first_delay = <2000>;
		vendor_use_sleep_mode;
		status = "okay";
	};
};

&exynos_is {
	vender {
		rear_sensor_id = <37>;	/* 2L4 */
		front_sensor_id = <31>; /* 3H1 */
		rear2_sensor_id = <64>;	/* 3M5 */
		rear3_sensor_id = <53>; /* 3P9 */
	};

	lic_offsets {
		/* 3AA = <setA lic offset0, setA lic offset1, set A trigger context */
		/*		setB lic offset0, setB lic offset1, set B trigger context> */
		/* 4672: 4640x4352 */
		/* 5824: 5804x4352 */
		3AA = <5461 10922 0 5461 10922 0>;
	};

	buffer_info {
		ypp_buf_max_width = <4608>;	/* defalut value : 5760 */
	};

	is_dvfs {
		#define DVFS_INT_CAM_L0 690000
		#define DVFS_INT_CAM_L1 680000
		#define DVFS_INT_CAM_L2 670000
		#define DVFS_INT_CAM_L3 660000
		#define DVFS_INT_CAM_L4 650000
		#define DVFS_INT_CAM_L5 640000
		#define DVFS_INT_CAM_L6 630000
		#define DVFS_INT_CAM_L7 620000

		#define DVFS_INT_L0 663000
		#define DVFS_INT_L1 468000
		#define DVFS_INT_L2 400000
		#define DVFS_INT_L3 267000
		#define DVFS_INT_L4 160000
		#define DVFS_INT_L5 89000

		#define DVFS_CSIS_L0 690000
		#define DVFS_CSIS_L1 680000
		#define DVFS_CSIS_L2 670000
		#define DVFS_CSIS_L3 660000
		#define DVFS_CSIS_L4 650000
		#define DVFS_CSIS_L5 640000
		#define DVFS_CSIS_L6 630000
		#define DVFS_CSIS_L7 620000

		#define DVFS_CAM_L0 690000
		#define DVFS_CAM_L1 680000
		#define DVFS_CAM_L2 670000
		#define DVFS_CAM_L3 660000
		#define DVFS_CAM_L4 650000
		#define DVFS_CAM_L5 640000
		#define DVFS_CAM_L6 630000
		#define DVFS_CAM_L7 620000

		#define DVFS_ISP_L0 690000
		#define DVFS_ISP_L1 680000
		#define DVFS_ISP_L2 670000
		#define DVFS_ISP_L3 660000
		#define DVFS_ISP_L4 650000
		#define DVFS_ISP_L5 640000
		#define DVFS_ISP_L6 630000
		#define DVFS_ISP_L7 620000

		#define DVFS_MIF_L0 3172000
		#define DVFS_MIF_L1 2730000
		#define DVFS_MIF_L2 2535000
		#define DVFS_MIF_L3 2288000
		#define DVFS_MIF_L4 2093000
		#define DVFS_MIF_L5 1716000
		#define DVFS_MIF_L6 1539000
		#define DVFS_MIF_L7 1352000
		#define DVFS_MIF_L8 1014000
		#define DVFS_MIF_L9 845000
		#define DVFS_MIF_L10 676000
		#define DVFS_MIF_L11 546000
		#define DVFS_MIF_L12 421000

		table0 {
			desc = "dvfs table v0.2";

			default_int_cam = <DVFS_INT_CAM_L0>;
			default_cam = <DVFS_CAM_L0>;
			default_csis = <DVFS_CSIS_L0>;
			default_isp = <DVFS_ISP_L0>;
			default_mif = <DVFS_MIF_L0>;
			default_int = <DVFS_INT_L0>;
			default_hpg = <1>;

			rear_single_wide_photo_int_cam = <DVFS_INT_CAM_L4>;
			rear_single_wide_photo_cam = <DVFS_CAM_L4>;
			rear_single_wide_photo_csis = <DVFS_CSIS_L4>;
			rear_single_wide_photo_isp = <DVFS_ISP_L4>;
			rear_single_wide_photo_mif = <DVFS_MIF_L6>;
			rear_single_wide_photo_int = <DVFS_INT_L2>;
			rear_single_wide_photo_hpg = <1>;

			rear_single_wide_photo_full_int_cam = <DVFS_INT_CAM_L4>;
			rear_single_wide_photo_full_cam = <DVFS_CAM_L4>;
			rear_single_wide_photo_full_csis = <DVFS_CSIS_L4>;
			rear_single_wide_photo_full_isp = <DVFS_ISP_L4>;
			rear_single_wide_photo_full_mif = <DVFS_MIF_L4>;
			rear_single_wide_photo_full_int = <DVFS_INT_L1>;
			rear_single_wide_photo_full_hpg = <1>;

			rear_single_wide_video_fhd30_int_cam = <DVFS_INT_CAM_L6>;
			rear_single_wide_video_fhd30_cam = <DVFS_CAM_L4>;
			rear_single_wide_video_fhd30_csis = <DVFS_CSIS_L4>;
			rear_single_wide_video_fhd30_isp = <DVFS_ISP_L6>;
			rear_single_wide_video_fhd30_mif = <DVFS_MIF_L8>;
			rear_single_wide_video_fhd30_int = <DVFS_INT_L3>;
			rear_single_wide_video_fhd30_hpg = <1>;

			rear_single_wide_videohdr_int_cam = <DVFS_INT_CAM_L5>;
			rear_single_wide_videohdr_cam = <DVFS_CAM_L4>;
			rear_single_wide_videohdr_csis = <DVFS_CSIS_L4>;
			rear_single_wide_videohdr_isp = <DVFS_ISP_L6>;
			rear_single_wide_videohdr_mif = <DVFS_MIF_L4>;
			rear_single_wide_videohdr_int = <DVFS_INT_L1>;
			rear_single_wide_videohdr_hpg = <1>;

			rear_single_wide_video_fhd60_int_cam = <DVFS_INT_CAM_L5>;
			rear_single_wide_video_fhd60_cam = <DVFS_CAM_L4>;
			rear_single_wide_video_fhd60_csis = <DVFS_CSIS_L4>;
			rear_single_wide_video_fhd60_isp = <DVFS_ISP_L6>;
			rear_single_wide_video_fhd60_mif = <DVFS_MIF_L6>;
			rear_single_wide_video_fhd60_int = <DVFS_INT_L2>;
			rear_single_wide_video_fhd60_hpg = <1>;

			rear_single_wide_video_uhd30_int_cam = <DVFS_INT_CAM_L5>;
			rear_single_wide_video_uhd30_cam = <DVFS_CAM_L4>;
			rear_single_wide_video_uhd30_csis = <DVFS_CSIS_L4>;
			rear_single_wide_video_uhd30_isp = <DVFS_ISP_L6>;
			rear_single_wide_video_uhd30_mif = <DVFS_MIF_L6>;
			rear_single_wide_video_uhd30_int = <DVFS_INT_L2>;
			rear_single_wide_video_uhd30_hpg = <1>;

			rear_single_wide_video_uhd60_int_cam = <DVFS_INT_CAM_L2>;
			rear_single_wide_video_uhd60_cam = <DVFS_CAM_L4>;
			rear_single_wide_video_uhd60_csis = <DVFS_CSIS_L4>;
			rear_single_wide_video_uhd60_isp = <DVFS_ISP_L6>;
			rear_single_wide_video_uhd60_mif = <DVFS_MIF_L4>;
			rear_single_wide_video_uhd60_int = <DVFS_INT_L2>;
			rear_single_wide_video_uhd60_hpg = <1>;

			rear_single_wide_capture_int_cam = <DVFS_INT_CAM_L4>;
			rear_single_wide_capture_cam = <DVFS_CAM_L4>;
			rear_single_wide_capture_csis = <DVFS_CSIS_L4>;
			rear_single_wide_capture_isp = <DVFS_ISP_L4>;
			rear_single_wide_capture_mif = <DVFS_MIF_L4>;
			rear_single_wide_capture_int = <DVFS_INT_L1>;
			rear_single_wide_capture_hpg = <1>;

			rear_single_wide_video_fhd120_int_cam = <DVFS_INT_CAM_L6>;
			rear_single_wide_video_fhd120_cam = <DVFS_CAM_L4>;
			rear_single_wide_video_fhd120_csis = <DVFS_CSIS_L4>;
			rear_single_wide_video_fhd120_isp = <DVFS_ISP_L6>;
			rear_single_wide_video_fhd120_mif = <DVFS_MIF_L4>;
			rear_single_wide_video_fhd120_int = <DVFS_INT_L2>;
			rear_single_wide_video_fhd120_hpg = <1>;

			rear_single_wide_video_fhd240_int_cam = <DVFS_INT_CAM_L2>;
			rear_single_wide_video_fhd240_cam = <DVFS_CAM_L4>;
			rear_single_wide_video_fhd240_csis = <DVFS_CSIS_L4>;
			rear_single_wide_video_fhd240_isp = <DVFS_ISP_L3>;
			rear_single_wide_video_fhd240_mif = <DVFS_MIF_L4>;
			rear_single_wide_video_fhd240_int = <DVFS_INT_L1>;
			rear_single_wide_video_fhd240_hpg = <8>;

			rear_single_wide_video_fhd480_int_cam = <DVFS_INT_CAM_L3>;
			rear_single_wide_video_fhd480_cam = <DVFS_CAM_L3>;
			rear_single_wide_video_fhd480_csis = <DVFS_CSIS_L3>;
			rear_single_wide_video_fhd480_isp = <DVFS_ISP_L3>;
			rear_single_wide_video_fhd480_mif = <DVFS_MIF_L4>;
			rear_single_wide_video_fhd480_int = <DVFS_INT_L2>;
			rear_single_wide_video_fhd480_hpg = <1>;

			rear_single_wide_video_ssm_int_cam = <DVFS_INT_CAM_L3>;
			rear_single_wide_video_ssm_cam = <DVFS_CAM_L3>;
			rear_single_wide_video_ssm_csis = <DVFS_CSIS_L3>;
			rear_single_wide_video_ssm_isp = <DVFS_ISP_L3>;
			rear_single_wide_video_ssm_mif = <DVFS_MIF_L4>;
			rear_single_wide_video_ssm_int = <DVFS_INT_L2>;
			rear_single_wide_video_ssm_hpg = <1>;

			rear_single_ultrawide_photo_int_cam = <DVFS_INT_CAM_L4>;
			rear_single_ultrawide_photo_cam = <DVFS_CAM_L4>;
			rear_single_ultrawide_photo_csis = <DVFS_CSIS_L4>;
			rear_single_ultrawide_photo_isp = <DVFS_ISP_L4>;
			rear_single_ultrawide_photo_mif = <DVFS_MIF_L6>;
			rear_single_ultrawide_photo_int = <DVFS_INT_L2>;
			rear_single_ultrawide_photo_hpg = <1>;

			rear_single_ultrawide_video_fhd30_int_cam = <DVFS_INT_CAM_L6>;
			rear_single_ultrawide_video_fhd30_cam = <DVFS_CAM_L4>;
			rear_single_ultrawide_video_fhd30_csis = <DVFS_CSIS_L4>;
			rear_single_ultrawide_video_fhd30_isp = <DVFS_ISP_L6>;
			rear_single_ultrawide_video_fhd30_mif = <DVFS_MIF_L6>;
			rear_single_ultrawide_video_fhd30_int = <DVFS_INT_L2>;
			rear_single_ultrawide_video_fhd30_hpg = <1>;

			rear_single_ultrawide_video_uhd30_int_cam = <DVFS_INT_CAM_L6>;
			rear_single_ultrawide_video_uhd30_cam = <DVFS_CAM_L4>;
			rear_single_ultrawide_video_uhd30_csis = <DVFS_CSIS_L4>;
			rear_single_ultrawide_video_uhd30_isp = <DVFS_ISP_L4>;
			rear_single_ultrawide_video_uhd30_mif = <DVFS_MIF_L6>;
			rear_single_ultrawide_video_uhd30_int = <DVFS_INT_L2>;
			rear_single_ultrawide_video_uhd30_hpg = <1>;

			rear_single_ultrawide_capture_int_cam = <DVFS_INT_CAM_L4>;
			rear_single_ultrawide_capture_cam = <DVFS_CAM_L4>;
			rear_single_ultrawide_capture_csis = <DVFS_CSIS_L4>;
			rear_single_ultrawide_capture_isp = <DVFS_ISP_L4>;
			rear_single_ultrawide_capture_mif = <DVFS_MIF_L4>;
			rear_single_ultrawide_capture_int = <DVFS_INT_L1>;
			rear_single_ultrawide_capture_hpg = <1>;

			rear_single_tele_photo_int_cam = <DVFS_INT_CAM_L4>;
			rear_single_tele_photo_cam = <DVFS_CAM_L4>;
			rear_single_tele_photo_csis = <DVFS_CSIS_L4>;
			rear_single_tele_photo_isp = <DVFS_ISP_L4>;
			rear_single_tele_photo_mif = <DVFS_MIF_L6>;
			rear_single_tele_photo_int = <DVFS_INT_L2>;
			rear_single_tele_photo_hpg = <1>;

			rear_single_tele_video_fhd30_int_cam = <DVFS_INT_CAM_L6>;
			rear_single_tele_video_fhd30_cam = <DVFS_CAM_L4>;
			rear_single_tele_video_fhd30_csis = <DVFS_CSIS_L4>;
			rear_single_tele_video_fhd30_isp = <DVFS_ISP_L6>;
			rear_single_tele_video_fhd30_mif = <DVFS_MIF_L6>;
			rear_single_tele_video_fhd30_int = <DVFS_INT_L2>;
			rear_single_tele_video_fhd30_hpg = <1>;

			rear_single_tele_video_uhd30_int_cam = <DVFS_INT_CAM_L5>;
			rear_single_tele_video_uhd30_cam = <DVFS_CAM_L5>;
			rear_single_tele_video_uhd30_csis = <DVFS_CSIS_L4>;
			rear_single_tele_video_uhd30_isp = <DVFS_ISP_L5>;
			rear_single_tele_video_uhd30_mif = <DVFS_MIF_L6>;
			rear_single_tele_video_uhd30_int = <DVFS_INT_L2>;
			rear_single_tele_video_uhd30_hpg = <1>;

			rear_single_tele_video_8k24_int_cam = <DVFS_INT_CAM_L4>;
			rear_single_tele_video_8k24_cam = <DVFS_CAM_L1>;
			rear_single_tele_video_8k24_csis = <DVFS_CSIS_L1>;
			rear_single_tele_video_8k24_isp = <DVFS_ISP_L1>;
			rear_single_tele_video_8k24_mif = <DVFS_MIF_L4>;
			rear_single_tele_video_8k24_int = <DVFS_INT_L2>;
			rear_single_tele_video_8k24_hpg = <1>;

			rear_single_tele_video_8k30_int_cam = <DVFS_INT_CAM_L3>;
			rear_single_tele_video_8k30_cam = <DVFS_CAM_L1>;
			rear_single_tele_video_8k30_csis = <DVFS_CSIS_L1>;
			rear_single_tele_video_8k30_isp = <DVFS_ISP_L1>;
			rear_single_tele_video_8k30_mif = <DVFS_MIF_L4>;
			rear_single_tele_video_8k30_int = <DVFS_INT_L1>;
			rear_single_tele_video_8k30_hpg = <1>;

			rear_single_tele_capture_int_cam = <DVFS_INT_CAM_L3>;
			rear_single_tele_capture_cam = <DVFS_CAM_L3>;
			rear_single_tele_capture_csis = <DVFS_CSIS_L3>;
			rear_single_tele_capture_isp = <DVFS_ISP_L3>;
			rear_single_tele_capture_mif = <DVFS_MIF_L4>;
			rear_single_tele_capture_int = <DVFS_INT_L0>;
			rear_single_tele_capture_hpg = <1>;

			rear_single_tele_remosaic_photo_int_cam = <DVFS_INT_CAM_L3>;
			rear_single_tele_remosaic_photo_cam = <DVFS_CAM_L1>;
			rear_single_tele_remosaic_photo_csis = <DVFS_CSIS_L1>;
			rear_single_tele_remosaic_photo_isp = <DVFS_ISP_L1>;
			rear_single_tele_remosaic_photo_mif = <DVFS_MIF_L4>;
			rear_single_tele_remosaic_photo_int = <DVFS_INT_L2>;
			rear_single_tele_remosaic_photo_hpg = <1>;

			rear_single_tele_remosaic_capture_int_cam = <DVFS_INT_CAM_L3>;
			rear_single_tele_remosaic_capture_cam = <DVFS_CAM_L1>;
			rear_single_tele_remosaic_capture_csis = <DVFS_CSIS_L1>;
			rear_single_tele_remosaic_capture_isp = <DVFS_ISP_L1>;
			rear_single_tele_remosaic_capture_mif = <DVFS_MIF_L4>;
			rear_single_tele_remosaic_capture_int = <DVFS_INT_L0>;
			rear_single_tele_remosaic_capture_hpg = <1>;

			rear_dual_tele_ultrawide_photo_int_cam = <DVFS_INT_CAM_L6>;
			rear_dual_tele_ultrawide_photo_cam = <DVFS_CAM_L4>;
			rear_dual_tele_ultrawide_photo_csis = <DVFS_CSIS_L4>;
			rear_dual_tele_ultrawide_photo_isp = <DVFS_ISP_L6>;
			rear_dual_tele_ultrawide_photo_mif = <DVFS_MIF_L8>;
			rear_dual_tele_ultrawide_photo_int = <DVFS_INT_L3>;

			rear_dual_wide_tele_photo_int_cam = <DVFS_INT_CAM_L4>;
			rear_dual_wide_tele_photo_cam = <DVFS_CAM_L4>;
			rear_dual_wide_tele_photo_csis = <DVFS_CSIS_L4>;
			rear_dual_wide_tele_photo_isp = <DVFS_ISP_L4>;
			rear_dual_wide_tele_photo_mif = <DVFS_MIF_L4>;
			rear_dual_wide_tele_photo_int = <DVFS_INT_L0>;
			rear_dual_wide_tele_photo_hpg = <1>;

			rear_dual_wide_tele_video_fhd30_int_cam = <DVFS_INT_CAM_L6>;
			rear_dual_wide_tele_video_fhd30_cam = <DVFS_CAM_L4>;
			rear_dual_wide_tele_video_fhd30_csis = <DVFS_CSIS_L4>;
			rear_dual_wide_tele_video_fhd30_isp = <DVFS_ISP_L6>;
			rear_dual_wide_tele_video_fhd30_mif = <DVFS_MIF_L4>;
			rear_dual_wide_tele_video_fhd30_int = <DVFS_INT_L0>;
			rear_dual_wide_tele_video_fhd30_hpg = <1>;

			rear_dual_wide_tele_video_uhd30_int_cam = <DVFS_INT_CAM_L5>;
			rear_dual_wide_tele_video_uhd30_cam = <DVFS_CAM_L5>;
			rear_dual_wide_tele_video_uhd30_csis = <DVFS_CSIS_L4>;
			rear_dual_wide_tele_video_uhd30_isp = <DVFS_ISP_L5>;
			rear_dual_wide_tele_video_uhd30_mif = <DVFS_MIF_L4>;
			rear_dual_wide_tele_video_uhd30_int = <DVFS_INT_L0>;
			rear_dual_wide_tele_video_uhd30_hpg = <1>;

			rear_dual_wide_tele_capture_int_cam = <DVFS_INT_CAM_L4>;
			rear_dual_wide_tele_capture_cam = <DVFS_CAM_L4>;
			rear_dual_wide_tele_capture_csis = <DVFS_CSIS_L4>;
			rear_dual_wide_tele_capture_isp = <DVFS_ISP_L4>;
			rear_dual_wide_tele_capture_mif = <DVFS_MIF_L4>;
			rear_dual_wide_tele_capture_int = <DVFS_INT_L0>;
			rear_dual_wide_tele_capture_hpg = <1>;

			rear_dual_wide_ultrawide_photo_int_cam = <DVFS_INT_CAM_L3>;
			rear_dual_wide_ultrawide_photo_cam = <DVFS_CAM_L3>;
			rear_dual_wide_ultrawide_photo_csis = <DVFS_CSIS_L3>;
			rear_dual_wide_ultrawide_photo_isp = <DVFS_ISP_L3>;
			rear_dual_wide_ultrawide_photo_mif = <DVFS_MIF_L4>;
			rear_dual_wide_ultrawide_photo_int = <DVFS_INT_L0>;
			rear_dual_wide_ultrawide_photo_hpg = <1>;

			rear_dual_wide_ultrawide_video_fhd30_int_cam = <DVFS_INT_CAM_L3>;
			rear_dual_wide_ultrawide_video_fhd30_cam = <DVFS_CAM_L3>;
			rear_dual_wide_ultrawide_video_fhd30_csis = <DVFS_CSIS_L3>;
			rear_dual_wide_ultrawide_video_fhd30_isp = <DVFS_ISP_L3>;
			rear_dual_wide_ultrawide_video_fhd30_mif = <DVFS_MIF_L4>;
			rear_dual_wide_ultrawide_video_fhd30_int = <DVFS_INT_L0>;
			rear_dual_wide_ultrawide_video_fhd30_hpg = <1>;

			rear_dual_wide_ultrawide_video_uhd30_int_cam = <DVFS_INT_CAM_L3>;
			rear_dual_wide_ultrawide_video_uhd30_cam = <DVFS_CAM_L3>;
			rear_dual_wide_ultrawide_video_uhd30_csis = <DVFS_CSIS_L3>;
			rear_dual_wide_ultrawide_video_uhd30_isp = <DVFS_ISP_L3>;
			rear_dual_wide_ultrawide_video_uhd30_mif = <DVFS_MIF_L4>;
			rear_dual_wide_ultrawide_video_uhd30_int = <DVFS_INT_L0>;
			rear_dual_wide_ultrawide_video_uhd30_hpg = <1>;

			rear_dual_wide_ultrawide_capture_int_cam = <DVFS_INT_CAM_L3>;
			rear_dual_wide_ultrawide_capture_cam = <DVFS_CAM_L3>;
			rear_dual_wide_ultrawide_capture_csis = <DVFS_CSIS_L3>;
			rear_dual_wide_ultrawide_capture_isp = <DVFS_ISP_L3>;
			rear_dual_wide_ultrawide_capture_mif = <DVFS_MIF_L4>;
			rear_dual_wide_ultrawide_capture_int = <DVFS_INT_L0>;
			rear_dual_wide_ultrawide_capture_hpg = <1>;

			triple_photo_int_cam = <DVFS_INT_CAM_L3>;
			triple_photo_cam = <DVFS_CAM_L1>;
			triple_photo_csis = <DVFS_CSIS_L1>;
			triple_photo_isp = <DVFS_ISP_L1>;
			triple_photo_mif = <DVFS_MIF_L4>;
			triple_photo_int = <DVFS_INT_L0>;
			triple_photo_hpg = <1>;

			triple_video_fhd30_int_cam = <DVFS_INT_CAM_L3>;
			triple_video_fhd30_cam = <DVFS_CAM_L1>;
			triple_video_fhd30_csis = <DVFS_CSIS_L1>;
			triple_video_fhd30_isp = <DVFS_ISP_L1>;
			triple_video_fhd30_mif = <DVFS_MIF_L4>;
			triple_video_fhd30_int = <DVFS_INT_L0>;
			triple_video_fhd30_hpg = <1>;

			triple_video_uhd30_int_cam = <DVFS_INT_CAM_L3>;
			triple_video_uhd30_cam = <DVFS_CAM_L1>;
			triple_video_uhd30_csis = <DVFS_CSIS_L1>;
			triple_video_uhd30_isp = <DVFS_ISP_L1>;
			triple_video_uhd30_mif = <DVFS_MIF_L4>;
			triple_video_uhd30_int = <DVFS_INT_L0>;
			triple_video_uhd30_hpg = <1>;

			triple_video_fhd60_int_cam = <DVFS_INT_CAM_L3>;
			triple_video_fhd60_cam = <DVFS_CAM_L1>;
			triple_video_fhd60_csis = <DVFS_CSIS_L1>;
			triple_video_fhd60_isp = <DVFS_ISP_L1>;
			triple_video_fhd60_mif = <DVFS_MIF_L4>;
			triple_video_fhd60_int = <DVFS_INT_L0>;
			triple_video_fhd60_hpg = <1>;

			triple_video_uhd60_int_cam = <DVFS_INT_CAM_L3>;
			triple_video_uhd60_cam = <DVFS_CAM_L1>;
			triple_video_uhd60_csis = <DVFS_CSIS_L1>;
			triple_video_uhd60_isp = <DVFS_ISP_L1>;
			triple_video_uhd60_mif = <DVFS_MIF_L4>;
			triple_video_uhd60_int = <DVFS_INT_L0>;
			triple_video_uhd60_hpg = <1>;

			triple_capture_int_cam = <DVFS_INT_CAM_L3>;
			triple_capture_cam = <DVFS_CAM_L1>;
			triple_capture_csis = <DVFS_CSIS_L1>;
			triple_capture_isp = <DVFS_ISP_L1>;
			triple_capture_mif = <DVFS_MIF_L4>;
			triple_capture_int = <DVFS_INT_L0>;
			triple_capture_hpg = <1>;

			front_single_photo_int_cam = <DVFS_INT_CAM_L4>;
			front_single_photo_cam = <DVFS_CAM_L4>;
			front_single_photo_csis = <DVFS_CSIS_L4>;
			front_single_photo_isp = <DVFS_ISP_L4>;
			front_single_photo_mif = <DVFS_MIF_L6>;
			front_single_photo_int = <DVFS_INT_L2>;
			front_single_photo_hpg = <1>;

			front_single_video_fhd30_int_cam = <DVFS_INT_CAM_L6>;
			front_single_video_fhd30_cam = <DVFS_CAM_L4>;
			front_single_video_fhd30_csis = <DVFS_CSIS_L4>;
			front_single_video_fhd30_isp = <DVFS_ISP_L6>;
			front_single_video_fhd30_mif = <DVFS_MIF_L6>;
			front_single_video_fhd30_int = <DVFS_INT_L2>;
			front_single_video_fhd30_hpg = <1>;

			front_single_video_uhd30_int_cam = <DVFS_INT_CAM_L6>;
			front_single_video_uhd30_cam = <DVFS_CAM_L4>;
			front_single_video_uhd30_csis = <DVFS_CSIS_L4>;
			front_single_video_uhd30_isp = <DVFS_ISP_L6>;
			front_single_video_uhd30_mif = <DVFS_MIF_L6>;
			front_single_video_uhd30_int = <DVFS_INT_L2>;
			front_single_video_uhd30_hpg = <1>;

			front_single_video_fhd60_int_cam = <DVFS_INT_CAM_L6>;
			front_single_video_fhd60_cam = <DVFS_CAM_L4>;
			front_single_video_fhd60_csis = <DVFS_CSIS_L4>;
			front_single_video_fhd60_isp = <DVFS_ISP_L6>;
			front_single_video_fhd60_mif = <DVFS_MIF_L6>;
			front_single_video_fhd60_int = <DVFS_INT_L2>;
			front_single_video_fhd60_hpg = <1>;

			front_single_video_uhd60_int_cam = <DVFS_INT_CAM_L5>;
			front_single_video_uhd60_cam = <DVFS_CAM_L5>;
			front_single_video_uhd60_csis = <DVFS_CSIS_L5>;
			front_single_video_uhd60_isp = <DVFS_ISP_L5>;
			front_single_video_uhd60_mif = <DVFS_MIF_L4>;
			front_single_video_uhd60_int = <DVFS_INT_L2>;
			front_single_video_uhd60_hpg = <1>;

			front_single_capture_int_cam = <DVFS_INT_CAM_L4>;
			front_single_capture_cam = <DVFS_CAM_L4>;
			front_single_capture_csis = <DVFS_CSIS_L4>;
			front_single_capture_isp = <DVFS_ISP_L4>;
			front_single_capture_mif = <DVFS_MIF_L4>;
			front_single_capture_int = <DVFS_INT_L0>;
			front_single_capture_hpg = <1>;

			front_single_vt_int_cam = <DVFS_INT_CAM_L6>;
			front_single_vt_cam = <DVFS_CAM_L4>;
			front_single_vt_csis = <DVFS_CSIS_L4>;
			front_single_vt_isp = <DVFS_ISP_L6>;
			front_single_vt_mif = <DVFS_MIF_L8>;
			front_single_vt_int = <DVFS_INT_L2>;
			front_single_vt_hpg = <1>;

			front_single_video_fhd120_int_cam = <DVFS_INT_CAM_L6>;
			front_single_video_fhd120_cam = <DVFS_CAM_L5>;
			front_single_video_fhd120_csis = <DVFS_CSIS_L5>;
			front_single_video_fhd120_isp = <DVFS_ISP_L5>;
			front_single_video_fhd120_mif = <DVFS_MIF_L4>;
			front_single_video_fhd120_int = <DVFS_INT_L2>;
			front_single_video_fhd120_hpg = <1>;

			rear_single_wide_dualfps_int_cam = <DVFS_INT_CAM_L3>;
			rear_single_wide_dualfps_cam = <DVFS_CAM_L3>;	/* VOTF */
			rear_single_wide_dualfps_csis = <DVFS_CSIS_L4>;	/* VOTF */
			rear_single_wide_dualfps_isp = <DVFS_ISP_L3>;
			rear_single_wide_dualfps_mif = <DVFS_MIF_L4>;
			rear_single_wide_dualfps_int = <DVFS_INT_L1>;
			rear_single_wide_dualfps_hpg = <6>;

			rear_single_wide_fastae_int_cam = <DVFS_INT_CAM_L4>;
			rear_single_wide_fastae_cam = <DVFS_CAM_L3>;		/* VOTF */
			rear_single_wide_fastae_csis = <DVFS_CSIS_L3>;	/* VOTF */
			rear_single_wide_fastae_isp = <DVFS_ISP_L3>;
			rear_single_wide_fastae_mif = <DVFS_MIF_L4>;
			rear_single_wide_fastae_int = <DVFS_INT_L2>;
			rear_single_wide_fastae_hpg = <1>;

			pip_dual_photo_int_cam = <DVFS_INT_CAM_L3>;
			pip_dual_photo_cam = <DVFS_CAM_L4>;
			pip_dual_photo_csis = <DVFS_CSIS_L4>;
			pip_dual_photo_isp = <DVFS_ISP_L1>;
			pip_dual_photo_mif = <DVFS_MIF_L4>;
			pip_dual_photo_int = <DVFS_INT_L2>;
			pip_dual_photo_hpg = <1>;

			pip_dual_capture_int_cam = <DVFS_INT_CAM_L3>;
			pip_dual_capture_cam = <DVFS_CAM_L4>;
			pip_dual_capture_csis = <DVFS_CSIS_L4>;
			pip_dual_capture_isp = <DVFS_ISP_L1>;
			pip_dual_capture_mif = <DVFS_MIF_L4>;
			pip_dual_capture_int = <DVFS_INT_L0>;
			pip_dual_capture_hpg = <1>;

			pip_dual_video_fhd30_int_cam = <DVFS_INT_CAM_L3>;
			pip_dual_video_fhd30_cam = <DVFS_CAM_L4>;
			pip_dual_video_fhd30_csis = <DVFS_CSIS_L4>;
			pip_dual_video_fhd30_isp = <DVFS_ISP_L1>;
			pip_dual_video_fhd30_mif = <DVFS_MIF_L4>;
			pip_dual_video_fhd30_int = <DVFS_INT_L2>;
			pip_dual_video_fhd30_hpg = <1>;

			ext_rear_single_int_cam = <DVFS_INT_CAM_L5>;
			ext_rear_single_cam = <DVFS_CAM_L5>;
			ext_rear_single_csis = <DVFS_CSIS_L5>;
			ext_rear_single_isp = <DVFS_ISP_L5>;
			ext_rear_single_mif = <DVFS_MIF_L8>;
			ext_rear_single_int = <DVFS_INT_L2>;
			ext_rear_single_hpg = <1>;

			ext_front_secure_int_cam = <DVFS_INT_CAM_L5>;
			ext_front_secure_cam = <DVFS_CAM_L5>;
			ext_front_secure_csis = <DVFS_CSIS_L5>;
			ext_front_secure_isp = <DVFS_ISP_L5>;
			ext_front_secure_mif = <DVFS_MIF_L8>;
			ext_front_secure_int = <DVFS_INT_L2>;
			ext_front_secure_hpg = <1>;

			max_int_cam = <DVFS_INT_CAM_L0>;
			max_cam = <DVFS_CAM_L0>;
			max_csis = <DVFS_CSIS_L0>;
			max_isp = <DVFS_ISP_L0>;
			max_mif = <DVFS_MIF_L0>;
			max_int = <DVFS_INT_L0>;
			max_hpg = <1>;
		};
	};
};
